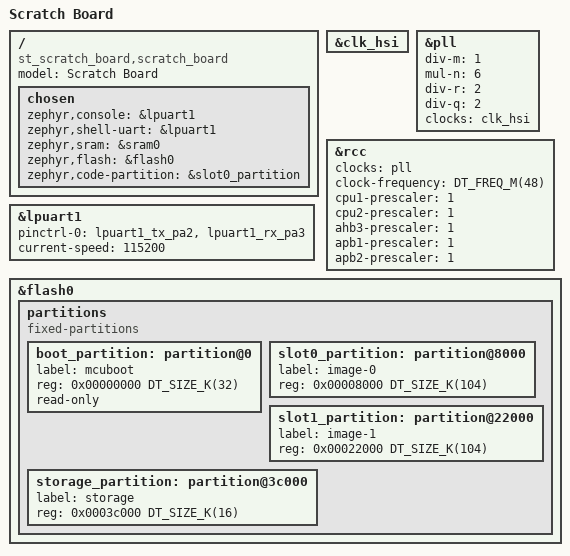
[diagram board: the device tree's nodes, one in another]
/dts-v1/;
#include <st/wl/stm32wl55Xc.dtsi>
#include <st/wl/stm32wl55jcix-pinctrl.dtsi>
#include <zephyr/dt-bindings/input/input-event-codes.h>

/ {
    model = "Scratch Board";
    compatible = "st_scratch_board,scratch_board";

    chosen {
		zephyr,console = &lpuart1;
		zephyr,shell-uart = &lpuart1;
		zephyr,sram = &sram0;
		zephyr,flash = &flash0;
		zephyr,code-partition = &slot0_partition;
    };
};

&clk_hsi {
	status = "okay";
};

&pll {
	div-m = <1>;
	mul-n = <6>;
	div-r = <2>;
	div-q = <2>;
	clocks = <&clk_hsi>;
	status = "okay";
};

&rcc {
	clocks = <&pll>;
	clock-frequency = <DT_FREQ_M(48)>;
	cpu1-prescaler = <1>;
	cpu2-prescaler = <1>;
	ahb3-prescaler = <1>;
	apb1-prescaler = <1>;
	apb2-prescaler = <1>;
};

&lpuart1 {
	pinctrl-0 = <&lpuart1_tx_pa2 &lpuart1_rx_pa3>;
	pinctrl-names = "default";
	current-speed = <115200>;
	status = "okay";
};

&flash0 {
	partitions {
		compatible = "fixed-partitions";
		#address-cells = <1>;
		#size-cells = <1>;

		boot_partition: partition@0 {
			label = "mcuboot";
			reg = <0x00000000 DT_SIZE_K(32)>;
			read-only;
		};

		slot0_partition: partition@8000 {
			label = "image-0";
			reg = <0x00008000 DT_SIZE_K(104)>;
		};

		slot1_partition: partition@22000 {
			label = "image-1";
			reg = <0x00022000 DT_SIZE_K(104)>;
		};

		/*
		 * Set 16kB of storage (8x2kB pages) at the end of the 256kB of
		 * flash.
		 */
		storage_partition: partition@3c000 {
			label = "storage";
			reg = <0x0003c000 DT_SIZE_K(16)>;
		};
	};
};
